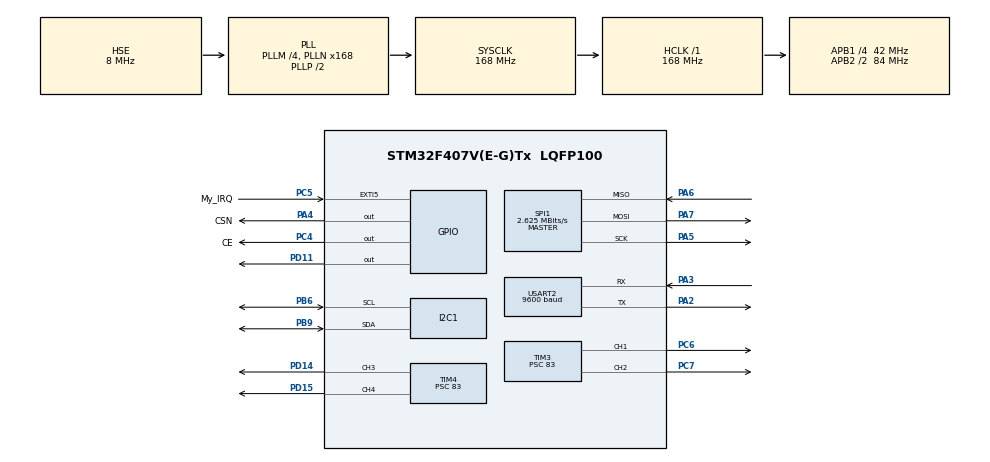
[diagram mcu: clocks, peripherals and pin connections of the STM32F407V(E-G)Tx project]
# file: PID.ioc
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I2C1.I2C_Mode=I2C_Fast
Mcu.Family=STM32F4
Mcu.Name=STM32F407V(E-G)Tx
Mcu.Package=LQFP100
NVIC.EXTI9_5_IRQn=true\:0\:0\:false\:false\:true\:true\:true\:true
NVIC.PriorityGroup=NVIC_PRIORITYGROUP_4
NVIC.RCC_IRQn=true\:0\:0\:false\:false\:true\:true\:false\:true
PA13.Mode=Serial_Wire
PA13.Signal=SYS_JTMS-SWDIO
PA14.Mode=Serial_Wire
PA14.Signal=SYS_JTCK-SWCLK
PA2.Mode=Asynchronous
PA2.Signal=USART2_TX
PA3.Mode=Asynchronous
PA3.Signal=USART2_RX
PA4.GPIO_Label=CSN
PA4.GPIO_Speed=GPIO_SPEED_FREQ_MEDIUM
PA4.Signal=GPIO_Output
PA5.Mode=Full_Duplex_Master
PA5.Signal=SPI1_SCK
PA6.Mode=Full_Duplex_Master
PA6.Signal=SPI1_MISO
PA7.Mode=Full_Duplex_Master
PA7.Signal=SPI1_MOSI
PB6.Mode=I2C
PB6.Signal=I2C1_SCL
PB9.Mode=I2C
PB9.Signal=I2C1_SDA
PC4.GPIO_Label=CE
PC4.GPIO_Speed=GPIO_SPEED_FREQ_MEDIUM
PC4.Signal=GPIO_Output
PC5.GPIO_Label=My_IRQ
PC5.GPIO_ModeDefaultEXTI=GPIO_MODE_IT_FALLING
PC5.Signal=GPXTI5
PC6.Signal=S_TIM3_CH1
PC7.Signal=S_TIM3_CH2
PD11.GPIO_Speed=GPIO_SPEED_FREQ_MEDIUM
PD11.Signal=GPIO_Output
PD14.Signal=S_TIM4_CH3
PD15.Signal=S_TIM4_CH4
PH0-OSC_IN.Mode=HSE-External-Oscillator
PH0-OSC_IN.Signal=RCC_OSC_IN
PH1-OSC_OUT.Mode=HSE-External-Oscillator
PH1-OSC_OUT.Signal=RCC_OSC_OUT
ProjectManager.HeapSize=0x200
ProjectManager.StackSize=0x400
ProjectManager.TargetToolchain=STM32CubeIDE
RCC.48MHZClocksFreq_Value=84000000
RCC.AHBFreq_Value=168000000
RCC.APB1CLKDivider=RCC_HCLK_DIV4
RCC.APB1Freq_Value=42000000
RCC.APB1TimFreq_Value=84000000
RCC.APB2CLKDivider=RCC_HCLK_DIV2
RCC.APB2Freq_Value=84000000
RCC.APB2TimFreq_Value=168000000
RCC.CortexFreq_Value=168000000
RCC.HCLKFreq_Value=168000000
RCC.HSE_VALUE=8000000
RCC.HSI_VALUE=16000000
RCC.LSE_VALUE=32768
RCC.PLLM=4
RCC.PLLN=168
RCC.PLLSourceVirtual=RCC_PLLSOURCE_HSE
RCC.SYSCLKFreq_VALUE=168000000
RCC.SYSCLKSource=RCC_SYSCLKSOURCE_PLLCLK
RCC.VCOOutputFreq_Value=336000000
SH.S_TIM3_CH1.0=TIM3_CH1,PWM Generation1 CH1
SH.S_TIM3_CH2.0=TIM3_CH2,PWM Generation2 CH2
SH.S_TIM4_CH3.0=TIM4_CH3,PWM Generation3 CH3
SH.S_TIM4_CH4.0=TIM4_CH4,PWM Generation4 CH4
SPI1.BaudRatePrescaler=SPI_BAUDRATEPRESCALER_32
SPI1.CLKPhase=SPI_PHASE_1EDGE
SPI1.CLKPolarity=SPI_POLARITY_LOW
SPI1.CalculateBaudRate=2.625 MBits/s
SPI1.Direction=SPI_DIRECTION_2LINES
SPI1.Mode=SPI_MODE_MASTER
SPI1.VirtualType=VM_MASTER
TIM3.AutoReloadPreload=TIM_AUTORELOAD_PRELOAD_DISABLE
TIM3.Channel-PWM\ Generation1\ CH1=TIM_CHANNEL_1
TIM3.Channel-PWM\ Generation2\ CH2=TIM_CHANNEL_2
TIM3.ClockDivision=TIM_CLOCKDIVISION_DIV1
TIM3.Period=19999
TIM3.Prescaler=83
TIM3.Pulse-PWM\ Generation1\ CH1=1000
TIM3.Pulse-PWM\ Generation2\ CH2=1000
TIM4.AutoReloadPreload=TIM_AUTORELOAD_PRELOAD_DISABLE
TIM4.Channel-PWM\ Generation3\ CH3=TIM_CHANNEL_3
TIM4.Channel-PWM\ Generation4\ CH4=TIM_CHANNEL_4
TIM4.Period=19999
TIM4.Prescaler=83
TIM4.Pulse-PWM\ Generation3\ CH3=1000
TIM4.Pulse-PWM\ Generation4\ CH4=1000
USART2.BaudRate=9600
USART2.Mode=MODE_TX_RX
USART2.OverSampling=UART_OVERSAMPLING_16
USART2.VirtualMode=VM_ASYNC
board=custom

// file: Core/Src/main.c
/* USER CODE BEGIN Header */
/**
  ******************************************************************************
  * @file           : main.c
  * @brief          : Main program body
  ******************************************************************************
  * @attention
  *
  * Copyright (c) 2026 STMicroelectronics.
  * All rights reserved.
  *
  * This software is licensed under terms that can be found in the LICENSE file
  * in the root directory of this software component.
  * If no LICENSE file comes with this software, it is provided AS-IS.
  *
  ******************************************************************************
  */
/* USER CODE END Header */
#include "main.h"

/* USER CODE BEGIN Includes */
#include "dwt_delay.h"
/* USER CODE END Includes */

I2C_HandleTypeDef hi2c1;

UART_HandleTypeDef huart2;

/* USER CODE BEGIN PV */
volatile uint8_t EXTI_5 = 0;
/* USER CODE END PV */

void SystemClock_Config(void);
static void MX_GPIO_Init(void);
static void MX_USART2_UART_Init(void);
static void MX_TIM3_Init(void);
static void MX_TIM4_Init(void);
static void MX_I2C1_Init(void);
static void MX_SPI1_Init(void);

int main(void)
{

  /* MCU Configuration--------------------------------------------------------*/

  /* Reset of all peripherals, Initializes the Flash interface and the Systick. */
  HAL_Init();

  /* Configure the system clock */
  SystemClock_Config();

  /* Initialize all configured peripherals */
  MX_GPIO_Init();
  MX_USART2_UART_Init();
  MX_TIM3_Init();
  MX_TIM4_Init();
  MX_I2C1_Init();
  MX_SPI1_Init();
  /* USER CODE BEGIN 2 */
  DWT_Init();
  /* USER CODE END 2 */

  /* Infinite loop */
  /* USER CODE BEGIN WHILE */
  loop();
  while (1)
  {

    /* USER CODE END WHILE */

  }
}

void SystemClock_Config(void)
{
  RCC_OscInitTypeDef RCC_OscInitStruct = {0};
  RCC_ClkInitTypeDef RCC_ClkInitStruct = {0};

  /** Configure the main internal regulator output voltage
  */
  __HAL_RCC_PWR_CLK_ENABLE();
  __HAL_PWR_VOLTAGESCALING_CONFIG(PWR_REGULATOR_VOLTAGE_SCALE1);

  /** Initializes the RCC Oscillators according to the specified parameters
  * in the RCC_OscInitTypeDef structure.
  */
  RCC_OscInitStruct.OscillatorType = RCC_OSCILLATORTYPE_HSE;
  RCC_OscInitStruct.HSEState = RCC_HSE_ON;
  RCC_OscInitStruct.PLL.PLLState = RCC_PLL_ON;
  RCC_OscInitStruct.PLL.PLLSource = RCC_PLLSOURCE_HSE;
  RCC_OscInitStruct.PLL.PLLM = 4;
  RCC_OscInitStruct.PLL.PLLN = 168;
  RCC_OscInitStruct.PLL.PLLP = RCC_PLLP_DIV2;
  RCC_OscInitStruct.PLL.PLLQ = 4;
  if (HAL_RCC_OscConfig(&RCC_OscInitStruct) != HAL_OK)
  {
    Error_Handler();
  }

  /** Initializes the CPU, AHB and APB buses clocks
  */
  RCC_ClkInitStruct.ClockType = RCC_CLOCKTYPE_HCLK|RCC_CLOCKTYPE_SYSCLK
                              |RCC_CLOCKTYPE_PCLK1|RCC_CLOCKTYPE_PCLK2;
  RCC_ClkInitStruct.SYSCLKSource = RCC_SYSCLKSOURCE_PLLCLK;
  RCC_ClkInitStruct.AHBCLKDivider = RCC_SYSCLK_DIV1;
  RCC_ClkInitStruct.APB1CLKDivider = RCC_HCLK_DIV4;
  RCC_ClkInitStruct.APB2CLKDivider = RCC_HCLK_DIV2;

  if (HAL_RCC_ClockConfig(&RCC_ClkInitStruct, FLASH_LATENCY_5) != HAL_OK)
  {
    Error_Handler();
  }
}

static void MX_I2C1_Init(void)
{

  hi2c1.Instance = I2C1;
  hi2c1.Init.ClockSpeed = 400000;
  hi2c1.Init.DutyCycle = I2C_DUTYCYCLE_2;
  hi2c1.Init.OwnAddress1 = 0;
  hi2c1.Init.AddressingMode = I2C_ADDRESSINGMODE_7BIT;
  hi2c1.Init.DualAddressMode = I2C_DUALADDRESS_DISABLE;
  hi2c1.Init.OwnAddress2 = 0;
  hi2c1.Init.GeneralCallMode = I2C_GENERALCALL_DISABLE;
  hi2c1.Init.NoStretchMode = I2C_NOSTRETCH_DISABLE;
  if (HAL_I2C_Init(&hi2c1) != HAL_OK)
  {
    Error_Handler();
  }

}

static void MX_SPI1_Init(void)
{

  LL_SPI_InitTypeDef SPI_InitStruct = {0};

  LL_GPIO_InitTypeDef GPIO_InitStruct = {0};

  /* Peripheral clock enable */
  LL_APB2_GRP1_EnableClock(LL_APB2_GRP1_PERIPH_SPI1);

  LL_AHB1_GRP1_EnableClock(LL_AHB1_GRP1_PERIPH_GPIOA);
  /**SPI1 GPIO Configuration
  PA5   ------> SPI1_SCK
  PA6   ------> SPI1_MISO
  PA7   ------> SPI1_MOSI
  */
  GPIO_InitStruct.Pin = LL_GPIO_PIN_5|LL_GPIO_PIN_6|LL_GPIO_PIN_7;
  GPIO_InitStruct.Mode = LL_GPIO_MODE_ALTERNATE;
  GPIO_InitStruct.Speed = LL_GPIO_SPEED_FREQ_VERY_HIGH;
  GPIO_InitStruct.OutputType = LL_GPIO_OUTPUT_PUSHPULL;
  GPIO_InitStruct.Pull = LL_GPIO_PULL_NO;
  GPIO_InitStruct.Alternate = LL_GPIO_AF_5;
  LL_GPIO_Init(GPIOA, &GPIO_InitStruct);

  /* SPI1 parameter configuration*/
  SPI_InitStruct.TransferDirection = LL_SPI_FULL_DUPLEX;
  SPI_InitStruct.Mode = LL_SPI_MODE_MASTER;
  SPI_InitStruct.DataWidth = LL_SPI_DATAWIDTH_8BIT;
  SPI_InitStruct.ClockPolarity = LL_SPI_POLARITY_LOW;
  SPI_InitStruct.ClockPhase = LL_SPI_PHASE_1EDGE;
  SPI_InitStruct.NSS = LL_SPI_NSS_SOFT;
  SPI_InitStruct.BaudRate = LL_SPI_BAUDRATEPRESCALER_DIV32;
  SPI_InitStruct.BitOrder = LL_SPI_MSB_FIRST;
  SPI_InitStruct.CRCCalculation = LL_SPI_CRCCALCULATION_DISABLE;
  SPI_InitStruct.CRCPoly = 10;
  LL_SPI_Init(SPI1, &SPI_InitStruct);
  LL_SPI_SetStandard(SPI1, LL_SPI_PROTOCOL_MOTOROLA);

}

static void MX_TIM3_Init(void)
{

  LL_TIM_InitTypeDef TIM_InitStruct = {0};
  LL_TIM_OC_InitTypeDef TIM_OC_InitStruct = {0};

  LL_GPIO_InitTypeDef GPIO_InitStruct = {0};

  /* Peripheral clock enable */
  LL_APB1_GRP1_EnableClock(LL_APB1_GRP1_PERIPH_TIM3);

  TIM_InitStruct.Prescaler = 83;
  TIM_InitStruct.CounterMode = LL_TIM_COUNTERMODE_UP;
  TIM_InitStruct.Autoreload = 19999;
  TIM_InitStruct.ClockDivision = LL_TIM_CLOCKDIVISION_DIV1;
  LL_TIM_Init(TIM3, &TIM_InitStruct);
  LL_TIM_DisableARRPreload(TIM3);
  LL_TIM_OC_EnablePreload(TIM3, LL_TIM_CHANNEL_CH1);
  TIM_OC_InitStruct.OCMode = LL_TIM_OCMODE_PWM1;
  TIM_OC_InitStruct.OCState = LL_TIM_OCSTATE_DISABLE;
  TIM_OC_InitStruct.OCNState = LL_TIM_OCSTATE_DISABLE;
  TIM_OC_InitStruct.CompareValue = 1000;
  TIM_OC_InitStruct.OCPolarity = LL_TIM_OCPOLARITY_HIGH;
  LL_TIM_OC_Init(TIM3, LL_TIM_CHANNEL_CH1, &TIM_OC_InitStruct);
  LL_TIM_OC_DisableFast(TIM3, LL_TIM_CHANNEL_CH1);
  LL_TIM_OC_EnablePreload(TIM3, LL_TIM_CHANNEL_CH2);
  LL_TIM_OC_Init(TIM3, LL_TIM_CHANNEL_CH2, &TIM_OC_InitStruct);
  LL_TIM_OC_DisableFast(TIM3, LL_TIM_CHANNEL_CH2);
  LL_TIM_SetTriggerOutput(TIM3, LL_TIM_TRGO_RESET);
  LL_TIM_DisableMasterSlaveMode(TIM3);
  LL_AHB1_GRP1_EnableClock(LL_AHB1_GRP1_PERIPH_GPIOC);
  /**TIM3 GPIO Configuration
  PC6   ------> TIM3_CH1
  PC7   ------> TIM3_CH2
  */
  GPIO_InitStruct.Pin = LL_GPIO_PIN_6|LL_GPIO_PIN_7;
  GPIO_InitStruct.Mode = LL_GPIO_MODE_ALTERNATE;
  GPIO_InitStruct.Speed = LL_GPIO_SPEED_FREQ_LOW;
  GPIO_InitStruct.OutputType = LL_GPIO_OUTPUT_PUSHPULL;
  GPIO_InitStruct.Pull = LL_GPIO_PULL_NO;
  GPIO_InitStruct.Alternate = LL_GPIO_AF_2;
  LL_GPIO_Init(GPIOC, &GPIO_InitStruct);

}

static void MX_TIM4_Init(void)
{

  LL_TIM_InitTypeDef TIM_InitStruct = {0};
  LL_TIM_OC_InitTypeDef TIM_OC_InitStruct = {0};

  LL_GPIO_InitTypeDef GPIO_InitStruct = {0};

  /* Peripheral clock enable */
  LL_APB1_GRP1_EnableClock(LL_APB1_GRP1_PERIPH_TIM4);

  TIM_InitStruct.Prescaler = 83;
  TIM_InitStruct.CounterMode = LL_TIM_COUNTERMODE_UP;
  TIM_InitStruct.Autoreload = 19999;
  TIM_InitStruct.ClockDivision = LL_TIM_CLOCKDIVISION_DIV1;
  LL_TIM_Init(TIM4, &TIM_InitStruct);
  LL_TIM_DisableARRPreload(TIM4);
  LL_TIM_OC_EnablePreload(TIM4, LL_TIM_CHANNEL_CH3);
  TIM_OC_InitStruct.OCMode = LL_TIM_OCMODE_PWM1;
  TIM_OC_InitStruct.OCState = LL_TIM_OCSTATE_DISABLE;
  TIM_OC_InitStruct.OCNState = LL_TIM_OCSTATE_DISABLE;
  TIM_OC_InitStruct.CompareValue = 1000;
  TIM_OC_InitStruct.OCPolarity = LL_TIM_OCPOLARITY_HIGH;
  LL_TIM_OC_Init(TIM4, LL_TIM_CHANNEL_CH3, &TIM_OC_InitStruct);
  LL_TIM_OC_DisableFast(TIM4, LL_TIM_CHANNEL_CH3);
  LL_TIM_OC_EnablePreload(TIM4, LL_TIM_CHANNEL_CH4);
  LL_TIM_OC_Init(TIM4, LL_TIM_CHANNEL_CH4, &TIM_OC_InitStruct);
  LL_TIM_OC_DisableFast(TIM4, LL_TIM_CHANNEL_CH4);
  LL_TIM_SetTriggerOutput(TIM4, LL_TIM_TRGO_RESET);
  LL_TIM_DisableMasterSlaveMode(TIM4);
  LL_AHB1_GRP1_EnableClock(LL_AHB1_GRP1_PERIPH_GPIOD);
  /**TIM4 GPIO Configuration
  PD14   ------> TIM4_CH3
  PD15   ------> TIM4_CH4
  */
  GPIO_InitStruct.Pin = LL_GPIO_PIN_14|LL_GPIO_PIN_15;
  GPIO_InitStruct.Mode = LL_GPIO_MODE_ALTERNATE;
  GPIO_InitStruct.Speed = LL_GPIO_SPEED_FREQ_LOW;
  GPIO_InitStruct.OutputType = LL_GPIO_OUTPUT_PUSHPULL;
  GPIO_InitStruct.Pull = LL_GPIO_PULL_NO;
  GPIO_InitStruct.Alternate = LL_GPIO_AF_2;
  LL_GPIO_Init(GPIOD, &GPIO_InitStruct);

}

static void MX_USART2_UART_Init(void)
{

  huart2.Instance = USART2;
  huart2.Init.BaudRate = 9600;
  huart2.Init.WordLength = UART_WORDLENGTH_8B;
  huart2.Init.StopBits = UART_STOPBITS_1;
  huart2.Init.Parity = UART_PARITY_NONE;
  huart2.Init.Mode = UART_MODE_TX_RX;
  huart2.Init.HwFlowCtl = UART_HWCONTROL_NONE;
  huart2.Init.OverSampling = UART_OVERSAMPLING_16;
  if (HAL_UART_Init(&huart2) != HAL_OK)
  {
    Error_Handler();
  }

}

static void MX_GPIO_Init(void)
{
  LL_EXTI_InitTypeDef EXTI_InitStruct = {0};
  LL_GPIO_InitTypeDef GPIO_InitStruct = {0};

  /* GPIO Ports Clock Enable */
  LL_AHB1_GRP1_EnableClock(LL_AHB1_GRP1_PERIPH_GPIOH);
  LL_AHB1_GRP1_EnableClock(LL_AHB1_GRP1_PERIPH_GPIOA);
  LL_AHB1_GRP1_EnableClock(LL_AHB1_GRP1_PERIPH_GPIOC);
  LL_AHB1_GRP1_EnableClock(LL_AHB1_GRP1_PERIPH_GPIOD);
  LL_AHB1_GRP1_EnableClock(LL_AHB1_GRP1_PERIPH_GPIOB);

  /**/
  LL_GPIO_ResetOutputPin(CSN_GPIO_Port, CSN_Pin);

  /**/
  LL_GPIO_ResetOutputPin(CE_GPIO_Port, CE_Pin);

  /**/
  LL_GPIO_ResetOutputPin(GPIOD, LL_GPIO_PIN_11);

  /**/
  GPIO_InitStruct.Pin = CSN_Pin;
  GPIO_InitStruct.Mode = LL_GPIO_MODE_OUTPUT;
  GPIO_InitStruct.Speed = LL_GPIO_SPEED_FREQ_MEDIUM;
  GPIO_InitStruct.OutputType = LL_GPIO_OUTPUT_PUSHPULL;
  GPIO_InitStruct.Pull = LL_GPIO_PULL_NO;
  LL_GPIO_Init(CSN_GPIO_Port, &GPIO_InitStruct);

  /**/
  GPIO_InitStruct.Pin = CE_Pin;
  GPIO_InitStruct.Mode = LL_GPIO_MODE_OUTPUT;
  GPIO_InitStruct.Speed = LL_GPIO_SPEED_FREQ_MEDIUM;
  GPIO_InitStruct.OutputType = LL_GPIO_OUTPUT_PUSHPULL;
  GPIO_InitStruct.Pull = LL_GPIO_PULL_NO;
  LL_GPIO_Init(CE_GPIO_Port, &GPIO_InitStruct);

  /**/
  GPIO_InitStruct.Pin = LL_GPIO_PIN_11;
  GPIO_InitStruct.Mode = LL_GPIO_MODE_OUTPUT;
  GPIO_InitStruct.Speed = LL_GPIO_SPEED_FREQ_MEDIUM;
  GPIO_InitStruct.OutputType = LL_GPIO_OUTPUT_PUSHPULL;
  GPIO_InitStruct.Pull = LL_GPIO_PULL_NO;
  LL_GPIO_Init(GPIOD, &GPIO_InitStruct);

  /**/
  LL_SYSCFG_SetEXTISource(LL_SYSCFG_EXTI_PORTC, LL_SYSCFG_EXTI_LINE5);

  /**/
  EXTI_InitStruct.Line_0_31 = LL_EXTI_LINE_5;
  EXTI_InitStruct.LineCommand = ENABLE;
  EXTI_InitStruct.Mode = LL_EXTI_MODE_IT;
  EXTI_InitStruct.Trigger = LL_EXTI_TRIGGER_FALLING;
  LL_EXTI_Init(&EXTI_InitStruct);

  /**/
  LL_GPIO_SetPinPull(My_IRQ_GPIO_Port, My_IRQ_Pin, LL_GPIO_PULL_NO);

  /**/
  LL_GPIO_SetPinMode(My_IRQ_GPIO_Port, My_IRQ_Pin, LL_GPIO_MODE_INPUT);

  /* EXTI interrupt init*/
  NVIC_SetPriority(EXTI9_5_IRQn, NVIC_EncodePriority(NVIC_GetPriorityGrouping(),0, 0));
  NVIC_EnableIRQ(EXTI9_5_IRQn);

}

void Error_Handler(void)
{
  __disable_irq();
  while (1)
  {
  }
}
